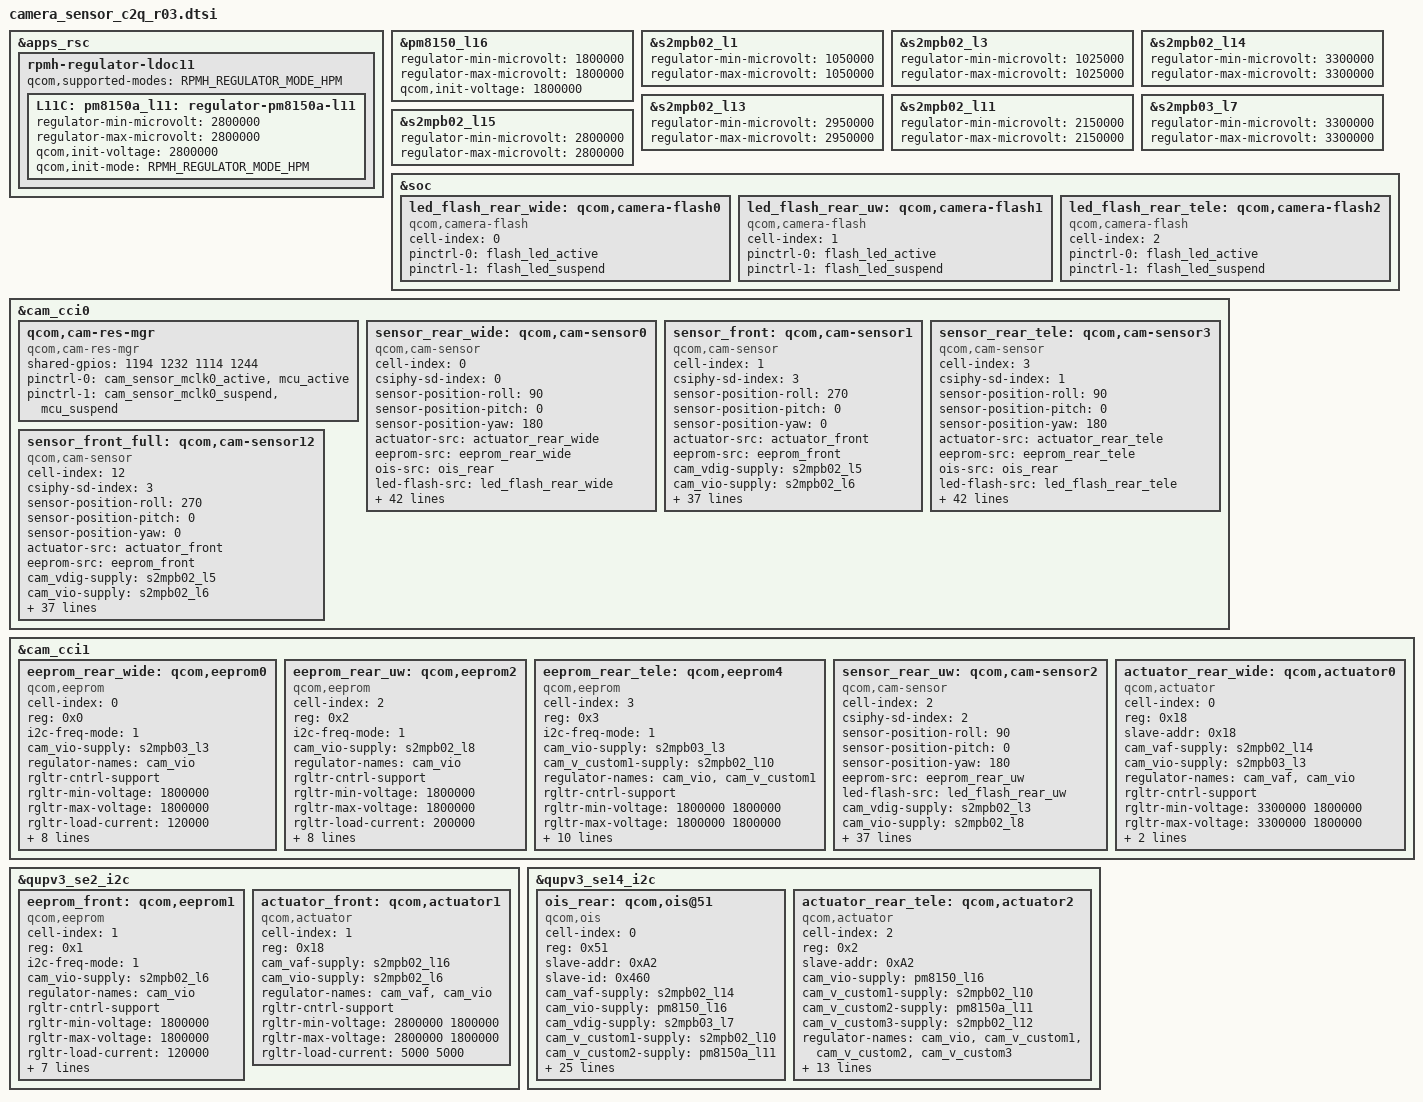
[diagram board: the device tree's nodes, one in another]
&apps_rsc {
	rpmh-regulator-ldoc11 {
		/delete-property/ qcom,supported-modes;
		qcom,supported-modes = <RPMH_REGULATOR_MODE_HPM>;
		L11C: pm8150a_l11: regulator-pm8150a-l11 {
			/delete-property/ qcom,proxy-consumer-enable;
			/delete-property/ qcom,proxy-consumer-current;
			regulator-min-microvolt = <2800000>;
			regulator-max-microvolt = <2800000>;
			qcom,init-voltage = <2800000>;
			qcom,init-mode = <RPMH_REGULATOR_MODE_HPM>;
		};
	};
};

&pm8150_l16 {
	regulator-min-microvolt = <1800000>;
	regulator-max-microvolt = <1800000>;
	qcom,init-voltage = <1800000>;
};

&s2mpb02_l1{
	regulator-min-microvolt = <1050000>;
	regulator-max-microvolt = <1050000>;
};

&s2mpb02_l3 {
	regulator-min-microvolt = <1025000>;
	regulator-max-microvolt = <1025000>;
};

&s2mpb02_l14 {
	regulator-min-microvolt = <3300000>;
	regulator-max-microvolt = <3300000>;
};

&s2mpb02_l13 {
	regulator-min-microvolt = <2950000>;
	regulator-max-microvolt = <2950000>;
};

&s2mpb02_l11 {
	regulator-min-microvolt = <2150000>;
	regulator-max-microvolt = <2150000>;
};

&s2mpb03_l7 {
	regulator-min-microvolt = <3300000>;
	regulator-max-microvolt = <3300000>;
};

&s2mpb02_l15 {
	regulator-min-microvolt = <2800000>;
	regulator-max-microvolt = <2800000>;
};

&soc {
	led_flash_rear_wide: qcom,camera-flash0 {
		cell-index = <0>;
		compatible = "qcom,camera-flash";
		pinctrl-names = "cam_default", "cam_suspend";
		pinctrl-0 = <&flash_led_active>;
		pinctrl-1 = <&flash_led_suspend>;
		status = "ok";
	};

	led_flash_rear_uw: qcom,camera-flash1 {
		cell-index = <1>;
		compatible = "qcom,camera-flash";
		pinctrl-names = "cam_default", "cam_suspend";
		pinctrl-0 = <&flash_led_active>;
		pinctrl-1 = <&flash_led_suspend>;
		status = "ok";
	};

	led_flash_rear_tele: qcom,camera-flash2 {
		cell-index = <2>;
		compatible = "qcom,camera-flash";
		pinctrl-names = "cam_default", "cam_suspend";
		pinctrl-0 = <&flash_led_active>;
		pinctrl-1 = <&flash_led_suspend>;
		status = "ok";
	};
};

&cam_cci0 {
	qcom,cam-res-mgr {
		compatible = "qcom,cam-res-mgr";
		shared-gpios = <1194 1232 1114 1244>;
		pinctrl-names = "cam_res_mgr_default", "cam_res_mgr_suspend";
		status = "ok";
		pinctrl-0 = <&cam_sensor_mclk0_active
					&mcu_active>;
		pinctrl-1 = <&cam_sensor_mclk0_suspend
					&mcu_suspend>;
	};

	sensor_rear_wide: qcom,cam-sensor0 {
		cell-index = <0>;
		compatible = "qcom,cam-sensor";
		csiphy-sd-index = <0>;
		sensor-position-roll = <90>;
		sensor-position-pitch = <0>;
		sensor-position-yaw = <180>;
		actuator-src = <&actuator_rear_wide>;
		eeprom-src = <&eeprom_rear_wide>;
		ois-src = <&ois_rear>;
		led-flash-src = <&led_flash_rear_wide>;
		cam_vdig-supply = <&s2mpb03_l2>;
		cam_vio-supply = <&s2mpb03_l3>;
		cam_vana-supply = <&s2mpb03_l5>;
		cam_v_custom1-supply = <&s2mpb02_l1>;
		cam_v_custom2-supply = <&s2mpb02_l10>; /* VDD_TELECAM_AF_OIS_IO_1P8 */
		cam_clk-supply = <&titan_top_gdsc>;
		regulator-names = "cam_vdig", "cam_vio", "cam_vana", "cam_clk", "cam_v_custom1", "cam_v_custom2";
		rgltr-cntrl-support;
		rgltr-min-voltage = <1100000 1800000 2800000 0 1050000 1800000>;
		rgltr-max-voltage = <1100000 1800000 2800000 0 1050000 1800000>;
		rgltr-load-current = <200000 200000 5000 0 5000 5000>;
		gpio-no-mux = <0>;
		use-shared-clk;
		pinctrl-names = "cam_default", "cam_suspend";
		pinctrl-0 = <&cam_sensor_active_rear>;
		pinctrl-1 = <&cam_sensor_suspend_rear>;
		gpios = <&tlmm 94 0>,
			<&tlmm 73 0>,
		        <&tlmm 144 0>;
		gpio-reset = <1>;
		gpio-custom1 = <2>;
		gpio-req-tbl-num = <0 1 2>;
		gpio-req-tbl-flags = <1 0 0>;
		gpio-req-tbl-label = "CAMIF_MCLK0",
					"CAM_RESET0",
					"MAINCAM_LDO_EN";
		sensor-mode = <0>;
		cci-master = <0>;
		status = "ok";
		clocks = <&clock_camcc CAM_CC_MCLK0_CLK>;
		clock-names = "cam_clk";
		clock-cntl-level = "turbo";
		clock-rates = <19200000>;

		cam,isp = <0>;                  // 0 : INT , 1 : EXT , 2 : SOC
		cam,cal_memory = <2>;           // 0 : N , 1 : FROM , 2 : EEPROM , 3 : OTP
		cam,read_version = <1>;         // 0 : SYSFS , 1 : CAMON
		cam,core_voltage = <1>;         // 0 : N , 1 : Y
		cam,upgrade = <2>;              // 0 : N , 1 : SYSFS , 2 : CAMON
		cam,fw_write = <3>;             // 0 : N , 1 : OS , 2 : SD , 3 : ALL
		cam,fw_dump = <1>;              // 0 : N , 1 : Y
		cam,companion_chip = <0>;       // 0 : N , 1 : Y
		cam,ois = <1>;                  // 0 : N , 1 : Y
		cam,dual_open = <0>;            // 0 : N , 1 : Y
		cam,valid = <1>;                // 0 : N , 1 : Y
	};

	sensor_front: qcom,cam-sensor1 {
		cell-index = <1>;
		compatible = "qcom,cam-sensor";
		csiphy-sd-index = <3>;
		sensor-position-roll = <270>;
		sensor-position-pitch = <0>;
		sensor-position-yaw = <0>;
		actuator-src = <&actuator_front>;
		eeprom-src = <&eeprom_front>;
		cam_vdig-supply = <&s2mpb02_l5>;
		cam_vio-supply = <&s2mpb02_l6>;
		cam_vana-supply = <&s2mpb02_l15>;
		cam_vaf-supply = <&s2mpb02_l16>;
		cam_clk-supply = <&titan_top_gdsc>;
		regulator-names = "cam_vdig", "cam_vio", "cam_vana", "cam_vaf", "cam_clk";
		rgltr-cntrl-support;
		rgltr-min-voltage = <1050000 1800000 2800000 2800000 0>;
		rgltr-max-voltage = <1050000 1800000 2800000 2800000 0>;
		rgltr-load-current = <200000 200000 5000 5000 0>;
		gpio-no-mux = <0>;
		pinctrl-names = "cam_default", "cam_suspend";
		pinctrl-0 = <&cam_sensor_mclk2_active
				&cam_sensor_active_front>;
		pinctrl-1 = <&cam_sensor_mclk2_suspend
				&cam_sensor_suspend_front>;
		gpios = <&tlmm 96 0>,
			<&tlmm 30 0>;
		gpio-reset = <1>;
		gpio-req-tbl-num = <0 1>;
		gpio-req-tbl-flags = <1 0>;
		gpio-req-tbl-label = "CAMIF_MCLK2",
					"CAM_RESET2";

		sensor-mode = <0>;
		cci-master = <1>;
		status = "ok";
		clocks = <&clock_camcc CAM_CC_MCLK2_CLK>;
		clock-names = "cam_clk";
		clock-cntl-level = "turbo";
		clock-rates = <24000000>;

		cam,isp = <0>;                  // 0 : INT , 1 : EXT , 2 : SOC
		cam,cal_memory = <2>;           // 0 : N , 1 : FROM , 2 : EEPROM , 3 : OTP
		cam,read_version = <0>;         // 0 : SYSFS , 1 : CAMON
		cam,core_voltage = <0>;         // 0 : N , 1 : Y
		cam,upgrade = <0>;              // 0 : N , 1 : SYSFS , 2 : CAMON
		cam,fw_write = <0>;             // 0 : N , 1 : OS , 2 : SD , 3 : ALL
		cam,fw_dump = <0>;              // 0 : N , 1 : Y
		cam,companion_chip = <0>;       // 0 : N , 1 : Y
		cam,ois = <0>;                  // 0 : N , 1 : Y
		cam,dual_open = <0>;            // 0 : N , 1 : Y
		cam,valid = <1>;                // 0 : N , 1 : Y
	};

	sensor_rear_tele: qcom,cam-sensor3 {
		cell-index = <3>;
		compatible = "qcom,cam-sensor";
		csiphy-sd-index = <1>;
		sensor-position-roll = <90>;
		sensor-position-pitch = <0>;
		sensor-position-yaw = <180>;
		actuator-src = <&actuator_rear_tele>;
		eeprom-src = <&eeprom_rear_tele>;
		ois-src = <&ois_rear>;
		led-flash-src = <&led_flash_rear_tele>;
		cam_vdig-supply = <&s2mpb03_l1>; /* VDD_TELECAM_1P05 */
		cam_vio-supply = <&s2mpb02_l7>; /* VDD_TELECAM_IO_1P8 */
		cam_vana-supply = <&s2mpb03_l6>; /* VDD_TELECAM_A2P9 */
		cam_v_custom1-supply = <&s2mpb02_l6>; /* VDD_VTCM_IO_1P8 */
		cam_v_custom2-supply = <&s2mpb02_l10>; /* VDD_TELECAM_AF_OIS_IO_1P8 */
		cam_clk-supply = <&titan_top_gdsc>;
		regulator-names = "cam_vdig", "cam_vio", "cam_vana", "cam_clk", "cam_v_custom1", "cam_v_custom2";
		rgltr-cntrl-support;
		rgltr-min-voltage = <1050000 1800000 2800000 0 1800000 1800000>;
		rgltr-max-voltage = <1050000 1800000 2800000 0 1800000 1800000>;
		rgltr-load-current = <200000 200000 5000 0 5000 5000>;
		gpio-no-mux = <0>;
		use-shared-clk;
		pinctrl-names = "cam_default", "cam_suspend";
		pinctrl-0 = <&cam_sensor_active_tele>;
		pinctrl-1 = <&cam_sensor_suspend_tele>;
		gpios = <&tlmm 94 0>,
			<&tlmm 150 0>,
			<&tlmm 144 0>;
		gpio-reset = <1>;
		gpio-custom1 = <2>;
		gpio-req-tbl-num = <0 1 2>;
		gpio-req-tbl-flags = <1 0 0>;
		gpio-req-tbl-label = "CAMIF_MCLK0",
					"CAM_RESET0",
					"MAINCAM_LDO_EN";
		sensor-mode = <0>;
		cci-master = <1>;
		status = "ok";
		clocks = <&clock_camcc CAM_CC_MCLK0_CLK>;
		clock-names = "cam_clk";
		clock-cntl-level = "turbo";
		clock-rates = <19200000>;

		cam,isp = <0>;                  // 0 : INT , 1 : EXT , 2 : SOC
		cam,cal_memory = <2>;           // 0 : N , 1 : FROM , 2 : EEPROM , 3 : OTP
		cam,read_version = <0>;         // 0 : SYSFS , 1 : CAMON
		cam,core_voltage = <0>;         // 0 : N , 1 : Y
		cam,upgrade = <0>;              // 0 : N , 1 : SYSFS , 2 : CAMON
		cam,fw_write = <0>;             // 0 : N , 1 : OS , 2 : SD , 3 : ALL
		cam,fw_dump = <0>;              // 0 : N , 1 : Y
		cam,companion_chip = <0>;       // 0 : N , 1 : Y
		cam,ois = <1>;                  // 0 : N , 1 : Y
		cam,dual_open = <0>;            // 0 : N , 1 : Y
		cam,valid = <1>;                // 0 : N , 1 : Y
	};

	sensor_front_full: qcom,cam-sensor12 {
		cell-index = <12>;
		compatible = "qcom,cam-sensor";
		csiphy-sd-index = <3>;
		sensor-position-roll = <270>;
		sensor-position-pitch = <0>;
		sensor-position-yaw = <0>;
		actuator-src = <&actuator_front>;
		eeprom-src = <&eeprom_front>;
		cam_vdig-supply = <&s2mpb02_l5>;
		cam_vio-supply = <&s2mpb02_l6>;
		cam_vana-supply = <&s2mpb02_l15>;
		cam_vaf-supply = <&s2mpb02_l16>;
		cam_clk-supply = <&titan_top_gdsc>;
		regulator-names = "cam_vdig", "cam_vio", "cam_vana", "cam_vaf", "cam_clk";
		rgltr-cntrl-support;
		rgltr-min-voltage = <1050000 1800000 2800000 2800000 0>;
		rgltr-max-voltage = <1050000 1800000 2800000 2800000 0>;
		rgltr-load-current = <200000 200000 5000 5000 0>;
		gpio-no-mux = <0>;
		pinctrl-names = "cam_default", "cam_suspend";
		pinctrl-0 = <&cam_sensor_mclk2_active
				&cam_sensor_active_front>;
		pinctrl-1 = <&cam_sensor_mclk2_suspend
				&cam_sensor_suspend_front>;
		gpios = <&tlmm 96 0>,
			<&tlmm 30 0>;
		gpio-reset = <1>;
		gpio-req-tbl-num = <0 1>;
		gpio-req-tbl-flags = <1 0>;
		gpio-req-tbl-label = "CAMIF_MCLK2",
					"CAM_RESET2";
		sensor-mode = <0>;
		cci-master = <1>;
		status = "ok";
		clocks = <&clock_camcc CAM_CC_MCLK2_CLK>;
		clock-names = "cam_clk";
		clock-cntl-level = "turbo";
		clock-rates = <19200000>;

		cam,isp = <0>;                  // 0 : INT , 1 : EXT , 2 : SOC
		cam,cal_memory = <2>;           // 0 : N , 1 : FROM , 2 : EEPROM , 3 : OTP
		cam,read_version = <0>;         // 0 : SYSFS , 1 : CAMON
		cam,core_voltage = <0>;         // 0 : N , 1 : Y
		cam,upgrade = <0>;              // 0 : N , 1 : SYSFS , 2 : CAMON
		cam,fw_write = <0>;             // 0 : N , 1 : OS , 2 : SD , 3 : ALL
		cam,fw_dump = <0>;              // 0 : N , 1 : Y
		cam,companion_chip = <0>;       // 0 : N , 1 : Y
		cam,ois = <0>;                  // 0 : N , 1 : Y
		cam,dual_open = <0>;            // 0 : N , 1 : Y
		cam,valid = <1>;                // 0 : N , 1 : Y
	};
};

&cam_cci1 {
	eeprom_rear_wide: qcom,eeprom0 {
		cell-index = <0>;
		reg = <0x0>;
		compatible = "qcom,eeprom";
		i2c-freq-mode = <1>;
		cam_vio-supply = <&s2mpb03_l3>;
		regulator-names = "cam_vio";
		rgltr-cntrl-support;
		rgltr-min-voltage = <1800000>;
		rgltr-max-voltage = <1800000>;
		rgltr-load-current = <120000>;
		qcom,cam-power-seq-type = "cam_vio";
		qcom,cam-power-seq-cfg-val = <1>;
		qcom,cam-power-seq-delay = <0>;
		gpio-no-mux = <0>;
		sensor-position = <1>;
		sensor-mode = <0>;
		cci-master = <1>;
		slave-addr = <0xA0>;

		status = "ok";
	};

	eeprom_rear_uw: qcom,eeprom2 {
		cell-index = <2>;
		reg = <0x2>;
		compatible = "qcom,eeprom";
		i2c-freq-mode = <1>;
		cam_vio-supply = <&s2mpb02_l8>;
		regulator-names = "cam_vio";
		rgltr-cntrl-support;
		rgltr-min-voltage = <1800000>;
		rgltr-max-voltage = <1800000>;
		rgltr-load-current = <200000>;
		qcom,cam-power-seq-type = "cam_vio";
		qcom,cam-power-seq-cfg-val = <1>;
		qcom,cam-power-seq-delay = <0>;
		gpio-no-mux = <0>;
		sensor-position = <1>;
		sensor-mode = <0>;
		cci-master = <0>;
		slave-addr = <0xA2>;

		status = "ok";
	};

	eeprom_rear_tele: qcom,eeprom4 {
		cell-index = <3>;
		reg = <0x3>;
		compatible = "qcom,eeprom";
		i2c-freq-mode = <1>;
		cam_vio-supply = <&s2mpb03_l3>;
		cam_v_custom1-supply = <&s2mpb02_l10>;
		regulator-names = "cam_vio" , "cam_v_custom1";
		rgltr-cntrl-support;
		rgltr-min-voltage = <1800000 1800000>;
		rgltr-max-voltage = <1800000 1800000>;
		rgltr-load-current = <120000 120000>;
		qcom,cam-power-seq-type = "cam_vio" , "cam_v_custom1";
		qcom,cam-power-seq-cfg-val = <1 1>;
		qcom,cam-power-seq-delay = <0 0>;
		gpio-no-mux = <0>;
		sensor-position = <1>;
		sensor-mode = <0>;
		cci-master = <1>;
		slave-addr = <0xA8>;

		status = "ok";
	};

	sensor_rear_uw: qcom,cam-sensor2 {
		cell-index = <2>;
		compatible = "qcom,cam-sensor";
		csiphy-sd-index = <2>;
		sensor-position-roll = <90>;
		sensor-position-pitch = <0>;
		sensor-position-yaw = <180>;
		eeprom-src = <&eeprom_rear_uw>;
		led-flash-src = <&led_flash_rear_uw>;
		cam_vdig-supply = <&s2mpb02_l3>;
		cam_vio-supply = <&s2mpb02_l8>;
		cam_vana-supply = <&s2mpb02_l13>;
		cam_v_custom1-supply = <&s2mpb02_l11>; /* VDD_UWCAM_A2P15 */
		cam_clk-supply = <&titan_top_gdsc>;
		regulator-names = "cam_vdig", "cam_vio", "cam_vana", "cam_v_custom1", "cam_clk";
		rgltr-cntrl-support;
		rgltr-min-voltage = <1025000 1800000 2950000 2150000 0>;
		rgltr-max-voltage = <1025000 1800000 2950000 2150000 0>;
		rgltr-load-current = <200000 200000 5000 5000 0>;
		gpio-no-mux = <0>;
		pinctrl-names = "cam_default", "cam_suspend";
		pinctrl-0 = <&cam_sensor_mclk1_active
				&cam_sensor_active_rear_aux>;
		pinctrl-1 = <&cam_sensor_mclk1_suspend
				&cam_sensor_suspend_rear_aux>;
		gpios = <&tlmm 95 0>,
			<&tlmm 78 0>;
		gpio-reset = <1>;
		gpio-req-tbl-num = <0 1>;
		gpio-req-tbl-flags = <1 0>;
		gpio-req-tbl-label = "CAMIF_MCLK1",
					"CAM_RESET1";
		sensor-mode = <0>;
		cci-master = <0>;
		status = "ok";
		clocks = <&clock_camcc CAM_CC_MCLK1_CLK>;
		clock-names = "cam_clk";
		clock-cntl-level = "turbo";
		clock-rates = <19200000>;

		cam,isp = <0>;                  // 0 : INT , 1 : EXT , 2 : SOC
		cam,cal_memory = <2>;           // 0 : N , 1 : FROM , 2 : EEPROM , 3 : OTP
		cam,read_version = <0>;         // 0 : SYSFS , 1 : CAMON
		cam,core_voltage = <0>;         // 0 : N , 1 : Y
		cam,upgrade = <0>;              // 0 : N , 1 : SYSFS , 2 : CAMON
		cam,fw_write = <0>;             // 0 : N , 1 : OS , 2 : SD , 3 : ALL
		cam,fw_dump = <0>;              // 0 : N , 1 : Y
		cam,companion_chip = <0>;       // 0 : N , 1 : Y
		cam,ois = <0>;                  // 0 : N , 1 : Y
		cam,dual_open = <0>;            // 0 : N , 1 : Y
		cam,valid = <1>;                // 0 : N , 1 : Y
	};

	actuator_rear_wide: qcom,actuator0 {
		cell-index = <0>;
		compatible = "qcom,actuator";
		reg = <0x18>;
		slave-addr = <0x18>;
		cam_vaf-supply = <&s2mpb02_l14>;
		cam_vio-supply = <&s2mpb03_l3>;
		regulator-names = "cam_vaf", "cam_vio";
		rgltr-cntrl-support;
		rgltr-min-voltage = <3300000 1800000>;
		rgltr-max-voltage = <3300000 1800000>;
		rgltr-load-current = <5000 5000>;
		cci-master = <1>;
		status = "ok";
	};
};

&qupv3_se2_i2c {
	status = "ok";
	// In C2Q REV03, we replace tof sensor with laser af sensor
	/delete-node/ qcom,qcom,cam-sensor4;
	/delete-node/ qcom,eeprom3;

	eeprom_front: qcom,eeprom1 {
		cell-index = <1>;
		reg = <0x1>;
		compatible = "qcom,eeprom";
		i2c-freq-mode = <1>;
		cam_vio-supply = <&s2mpb02_l6>;
		regulator-names = "cam_vio";
		rgltr-cntrl-support;
		rgltr-min-voltage = <1800000>;
		rgltr-max-voltage = <1800000>;
		rgltr-load-current = <120000>;
		qcom,cam-power-seq-type = "cam_vio";
		qcom,cam-power-seq-cfg-val = <1>;
		qcom,cam-power-seq-delay = <0>;
		gpio-no-mux = <0>;
		sensor-position = <1>;
		sensor-mode = <0>;

		slave-addr = <0xA0>;

		status = "ok";
	};

	actuator_front: qcom,actuator1 {
		cell-index = <1>;
		compatible = "qcom,actuator";
		reg = <0x18>;
		cam_vaf-supply = <&s2mpb02_l16>;
		cam_vio-supply = <&s2mpb02_l6>;
		regulator-names = "cam_vaf", "cam_vio";
		rgltr-cntrl-support;
		rgltr-min-voltage = <2800000 1800000>;
		rgltr-max-voltage = <2800000 1800000>;
		rgltr-load-current = <5000 5000>;
		status = "ok";
	};
};

&qupv3_se14_i2c {
	status = "ok";
	ois_rear: qcom,ois@51  {
		compatible = "qcom,ois";
		cell-index = <0>;
		reg = <0x51>;
		slave-addr = <0xA2>;
		slave-id = <0x460>;
		cam_vaf-supply = <&s2mpb02_l14>; /* VDD_MAINCAM_AF_3P3 */
		cam_vio-supply = <&pm8150_l16>; /* VDD_OIS_MCU_1P8 */
		cam_vdig-supply = <&s2mpb03_l7>; /* VDD_MAINCAM_OIS_3P3 */
		cam_v_custom1-supply = <&s2mpb02_l10>; /* VDD_TELECAM_AF_OIS_IO_1P8 */
		cam_v_custom2-supply = <&pm8150a_l11>; /* VDD_TELECAM_AF_OIS_VM_2P8 */
		cam_v_custom3-supply = <&s2mpb02_l12>; /* VDD_TELECAM_AF_OIS_A2P8 */
                cam_clk-supply = <&titan_top_gdsc>;
		regulator-names = "cam_vaf", "cam_vio", "cam_vdig", "cam_v_custom1", "cam_v_custom2", "cam_v_custom3", "cam_clk";
                use-shared-clk;
		rgltr-cntrl-support;
		rgltr-min-voltage = <3300000 1800000 3300000 1800000 2800000 2800000 0>;
		rgltr-max-voltage = <3300000 1800000 3300000 1800000 2800000 2800000 0>;
		rgltr-load-current = <5000 5000 5000 5000 5000 5000 0>;
		gpio-no-mux = <0>;
		gpios = <&tlmm 94 0>,  // MCLK0
		        <&tlmm 14 0>,  // RESET
			<&tlmm 118 0>, // BOOT0
			<&tlmm 132 0>; // TELECAM_OIS_RST
		gpio-reset = <1>;
		gpio-custom1 = <2>;
		gpio-custom2 = <3>;
		gpio-req-tbl-num = <0 1 2 3>;
		gpio-req-tbl-flags = <1 0 0 0>;
		gpio-req-tbl-label = "CAMIF_MCLK0", "MCU_RESET0", "MCU_BOOT0", "MCU_RESET1";
		status = "ok";

		clocks = <&clock_camcc CAM_CC_MCLK0_CLK>;
                clock-names = "cam_clk";
                clock-cntl-level = "turbo";
                clock-rates = <19200000>;
	};

	actuator_rear_tele: qcom,actuator2 {
		cell-index = <2>;
		compatible = "qcom,actuator";
		reg = <0x2>;
		slave-addr = <0xA2>;
		cam_vio-supply = <&pm8150_l16>;       /* VDD_OIS_MCU_1P8 */
		cam_v_custom1-supply = <&s2mpb02_l10>; /* VDD_TELECAM_AF_OIS_IO_1P8 */
		cam_v_custom2-supply = <&pm8150a_l11>; /* VDD_TELECAM_AF_OIS_VM_2P8 */
		cam_v_custom3-supply = <&s2mpb02_l12>; /* VDD_TELECAM_AF_OIS_A2P8 */
		regulator-names = "cam_vio", "cam_v_custom1", "cam_v_custom2", "cam_v_custom3";
		rgltr-cntrl-support;
		rgltr-min-voltage = <1800000 1800000 2800000 2800000>;
		rgltr-max-voltage = <1800000 1800000 2800000 2800000>;
		rgltr-load-current = <5000 5000 5000 5000>;
		gpio-no-mux = <0>;
		gpios = <&tlmm 14 0>, // RESET
			<&tlmm 132 0>; // TELECAM_OIS_RST
		gpio-reset = <0>;
		gpio-custom1 = <1>;
		gpio-req-tbl-num = <0 1>;
		gpio-req-tbl-flags = <0 0>;
		gpio-req-tbl-label = "MCU_RESET0", "MCU_RESET1";

		status = "ok";
	};
};

